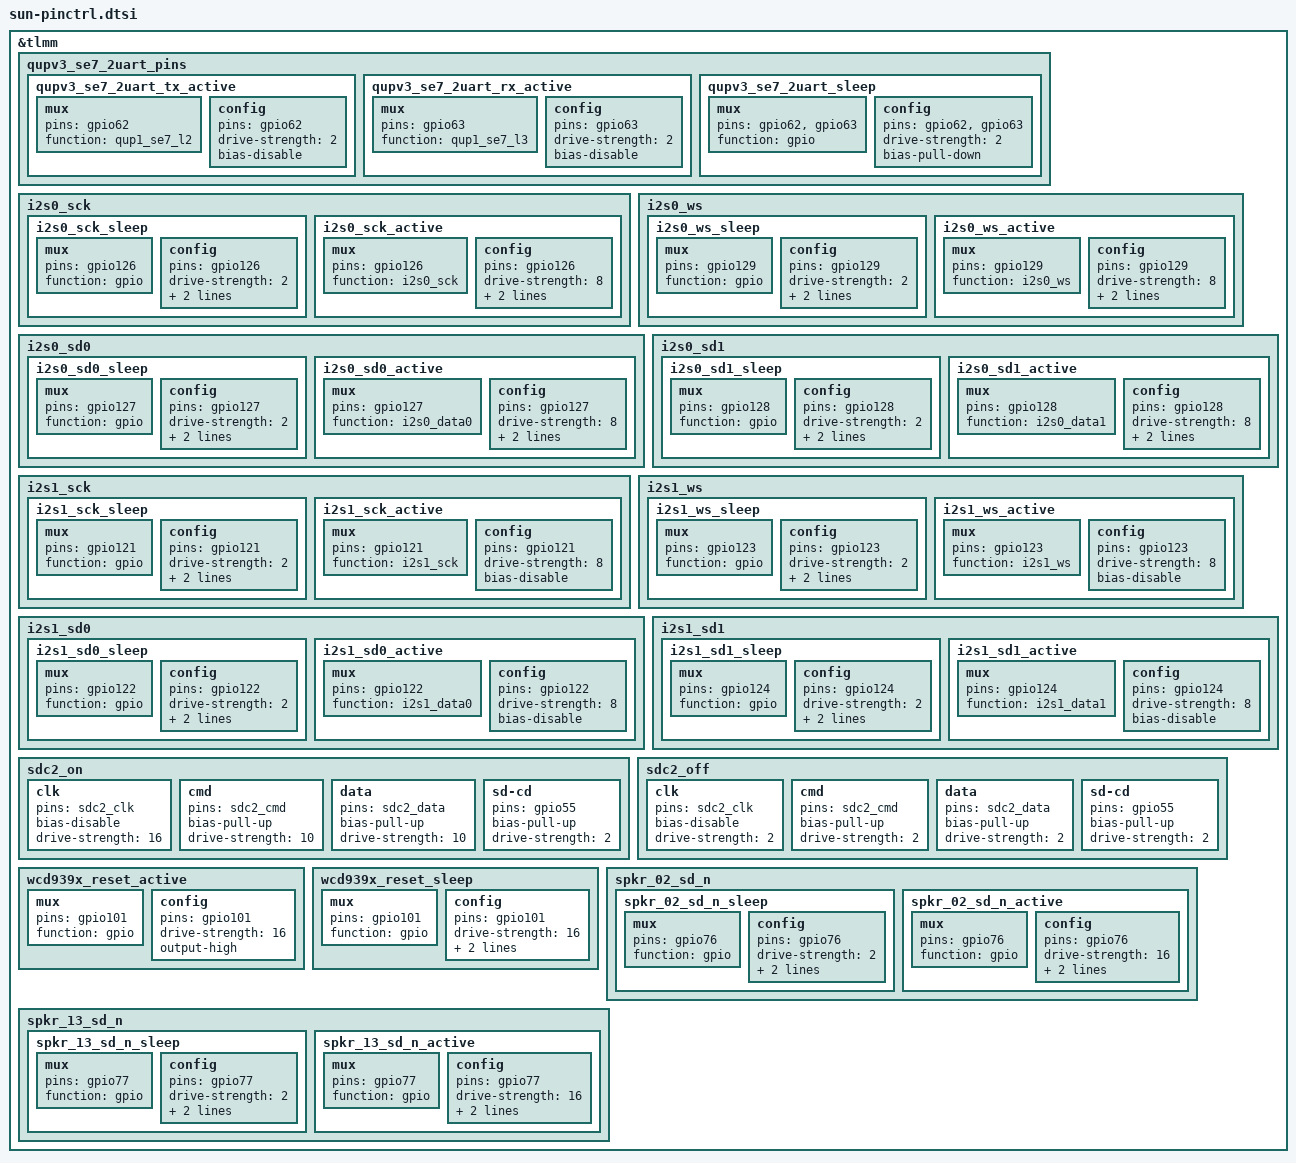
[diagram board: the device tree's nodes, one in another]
// SPDX-License-Identifier: BSD-3-Clause
/*
 * Copyright (c) 2023 Qualcomm Innovation Center, Inc. All rights reserved.
 */

&tlmm {
	qupv3_se7_2uart_pins: qupv3_se7_2uart_pins {
		qupv3_se7_2uart_tx_active: qupv3_se7_2uart_tx_active {
			mux {
				pins = "gpio62";
				function = "qup1_se7_l2";
			};

			config {
				pins = "gpio62";
				drive-strength = <2>;
				bias-disable;
			};
		};

		qupv3_se7_2uart_rx_active: qupv3_se7_2uart_rx_active {
			mux {
				pins = "gpio63";
				function = "qup1_se7_l3";
			};

			config {
				pins = "gpio63";
				drive-strength = <2>;
				bias-disable;
			};
		};

		qupv3_se7_2uart_sleep: qupv3_se7_2uart_sleep {
			mux {
				pins = "gpio62", "gpio63";
				function = "gpio";
			};

			config {
				pins = "gpio62", "gpio63";
				drive-strength = <2>;
				bias-pull-down;
			};
		};
	};

	i2s0_sck {
		i2s0_sck_sleep: i2s0_sck_sleep {
			mux {
				pins = "gpio126";
				function = "gpio";
			};

			config {
				pins = "gpio126";
				drive-strength = <2>;   /* 2 mA */
				bias-pull-down;         /* PULL DOWN */
				input-enable;
			};
		};

		i2s0_sck_active: i2s0_sck_active {
			mux {
				pins = "gpio126";
				function = "i2s0_sck";
			};

			config {
				pins = "gpio126";
				drive-strength = <8>;   /* 8 mA */
				bias-disable;           /* NO PULL */
				output-high;
			};
		};
	};

	i2s0_ws {
		i2s0_ws_sleep: i2s0_ws_sleep {
			mux {
				pins = "gpio129";
				function = "gpio";
			};

			config {
				pins = "gpio129";
				drive-strength = <2>;   /* 2 mA */
				bias-pull-down;         /* PULL DOWN */
				input-enable;
			};
		};

		i2s0_ws_active: i2s0_ws_active {
			mux {
				pins = "gpio129";
				function = "i2s0_ws";
			};

			config {
				pins = "gpio129";
				drive-strength = <8>;   /* 8 mA */
				bias-disable;           /* NO PULL */
				output-high;
			};
		};
	};

	i2s0_sd0 {
		i2s0_sd0_sleep: i2s0_sd0_sleep {
			mux {
				pins = "gpio127";
				function = "gpio";
			};

			config {
				pins = "gpio127";
				drive-strength = <2>;   /* 2 mA */
				bias-pull-down;         /* PULL DOWN */
				input-enable;
			};
		};

		i2s0_sd0_active: i2s0_sd0_active {
			mux {
				pins = "gpio127";
				function = "i2s0_data0";
			};

			config {
				pins = "gpio127";
				drive-strength = <8>;   /* 8 mA */
				bias-disable;           /* NO PULL */
				output-high;
			};
		};
	};

	i2s0_sd1 {
		i2s0_sd1_sleep: i2s0_sd1_sleep {
			mux {
				pins = "gpio128";
				function = "gpio";
			};

			config {
				pins = "gpio128";
				drive-strength = <2>;   /* 2 mA */
				bias-pull-down;         /* PULL DOWN */
				input-enable;
			};
		};

		i2s0_sd1_active: i2s0_sd1_active {
			mux {
				pins = "gpio128";
				function = "i2s0_data1";
			};

			config {
				pins = "gpio128";
				drive-strength = <8>;   /* 8 mA */
				bias-disable;           /* NO PULL */
				output-high;
			};
		};
	};

	i2s1_sck {
		i2s1_sck_sleep: i2s1_sck_sleep {
			mux {
				pins = "gpio121";
				function = "gpio";
			};

			config {
				pins = "gpio121";
				drive-strength = <2>;   /* 2 mA */
				bias-pull-down;         /* PULL DOWN */
				input-enable;
			};
		};

		i2s1_sck_active: i2s1_sck_active {
			mux {
				pins = "gpio121";
				function = "i2s1_sck";
			};

			config {
				pins = "gpio121";
				drive-strength = <8>;   /* 8 mA */
				bias-disable;           /* NO PULL */
			};
		};
	};

	i2s1_ws {
		i2s1_ws_sleep: i2s1_ws_sleep {
			mux {
				pins = "gpio123";
				function = "gpio";
			};

			config {
				pins = "gpio123";
				drive-strength = <2>;   /* 2 mA */
				bias-pull-down;         /* PULL DOWN */
				input-enable;
			};
		};

		i2s1_ws_active: i2s1_ws_active {
			mux {
				pins = "gpio123";
				function = "i2s1_ws";
			};

			config {
				pins = "gpio123";
				drive-strength = <8>;   /* 8 mA */
				bias-disable;           /* NO PULL */
			};
		};
	};

	i2s1_sd0 {
		i2s1_sd0_sleep: i2s1_sd0_sleep {
			mux {
				pins = "gpio122";
				function = "gpio";
			};

			config {
				pins = "gpio122";
				drive-strength = <2>;   /* 2 mA */
				bias-pull-down;         /* PULL DOWN */
				input-enable;
			};
		};

		i2s1_sd0_active: i2s1_sd0_active {
			mux {
				pins = "gpio122";
				function = "i2s1_data0";
			};

			config {
				pins = "gpio122";
				drive-strength = <8>;   /* 8 mA */
				bias-disable;           /* NO PULL */
			};
		};
	};

	i2s1_sd1 {
		i2s1_sd1_sleep: i2s1_sd1_sleep {
			mux {
				pins = "gpio124";
				function = "gpio";
			};

			config {
				pins = "gpio124";
				drive-strength = <2>;   /* 2 mA */
				bias-pull-down;         /* PULL DOWN */
				input-enable;
			};
		};

		i2s1_sd1_active: i2s1_sd1_active {
			mux {
				pins = "gpio124";
				function = "i2s1_data1";
			};

			config {
				pins = "gpio124";
				drive-strength = <8>;   /* 8 mA */
				bias-disable;           /* NO PULL */
			};
		};
	};

	sdc2_on: sdc2_on {
		clk {
			pins = "sdc2_clk";
			bias-disable;
			drive-strength = <16>;
		};

		cmd {
			pins = "sdc2_cmd";
			bias-pull-up;
			drive-strength = <10>;
		};

		data {
			pins = "sdc2_data";
			bias-pull-up;
			drive-strength = <10>;
		};

		sd-cd {
			pins = "gpio55";
			bias-pull-up;
			drive-strength = <2>;
		};
	};

	sdc2_off: sdc2_off {
		clk {
			pins = "sdc2_clk";
			bias-disable;
			drive-strength = <2>;
		};

		cmd {
			pins = "sdc2_cmd";
			bias-pull-up;
			drive-strength = <2>;
		};

		data {
			pins = "sdc2_data";
			bias-pull-up;
			drive-strength = <2>;
		};

		sd-cd {
			pins = "gpio55";
			bias-pull-up;
			drive-strength = <2>;
		};
	};

	/* WCD reset pin */
	wcd939x_reset_active: wcd939x_reset_active {
		mux {
			pins = "gpio101";
			function = "gpio";
		};

		config {
			pins = "gpio101";
			drive-strength = <16>;
			output-high;
		};
	};

	wcd939x_reset_sleep: wcd939x_reset_sleep {
		mux {
			pins = "gpio101";
			function = "gpio";
		};

		config {
			pins = "gpio101";
			drive-strength = <16>;
			bias-disable;
			output-low;
		};
	};

	/* WSA speaker - north reset pins */
	spkr_02_sd_n {
		spkr_02_sd_n_sleep: spkr_02_sd_n_sleep {
			mux {
				pins = "gpio76";
				function = "gpio";
			};

			config {
				pins = "gpio76";
				drive-strength = <2>;   /* 2 mA */
				bias-pull-down;
				input-enable;
			};
		};

		spkr_02_sd_n_active: spkr_02_sd_n_active {
			mux {
				pins = "gpio76";
				function = "gpio";
			};

			config {
				pins = "gpio76";
				drive-strength = <16>;   /* 16 mA */
				bias-disable;
				output-high;
			};
		};
	};

	/* WSA speaker - south reset pins */
	spkr_13_sd_n {
		spkr_13_sd_n_sleep: spkr_13_sd_n_sleep {
			mux {
				pins = "gpio77";
				function = "gpio";
			};

			config {
				pins = "gpio77";
				drive-strength = <2>;   /* 2 mA */
				bias-pull-down;
				input-enable;
			};
		};

		spkr_13_sd_n_active: spkr_13_sd_n_active {
			mux {
				pins = "gpio77";
				function = "gpio";
			};

			config {
				pins = "gpio77";
				drive-strength = <16>;   /* 16 mA */
				bias-disable;
				output-high;
			};
		};
	};
};
